AUTOSAR XML (schema 00044)
package /E40_Platform_System_SystemPackage/Components
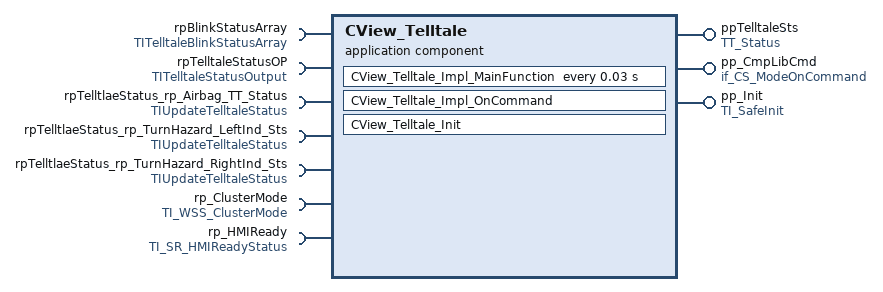
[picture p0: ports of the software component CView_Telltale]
  application sw component type CView_Telltale
    provide port ppTelltaleSts: nonqueued-sender-com-spec{data-element=TT_StatusData, init-value=constant-reference=CView_TelltaleTT_StatusDataValue0}, provided-interface=TT_Status
    provide port pp_CmpLibCmd: server-com-spec{operation=Impl_OnCommand, queue-length=1}, provided-interface=if_CS_ModeOnCommand
    provide port pp_Init: server-com-spec{operation=Init, queue-length=1}, provided-interface=TI_SafeInit
    7 x require port:
      rpBlinkStatusArray: required-interface=TITelltaleBlinkStatusArray
        required-com-specs:
          data-element=TTBlinkStatusArray, init-value=constant-reference=CView_TelltaleTTBlinkStatusArrayValue0
          data-element=TTdummyDataForTypes, init-value=constant-reference=CView_TelltaleTTdummyDataForTypesValue0
      rpTelltaleStatusOP: nonqueued-receiver-com-spec{data-element=TelltaleOpArray, init-value=constant-reference=CView_TelltaleTelltaleOpArrayValue0}, required-interface=TITelltaleStatusOutput
      rpTelltlaeStatus_rp_Airbag_TT_Status: nonqueued-receiver-com-spec{data-element=CurrentTelltaleStatus, init-value=constant-reference=CView_TelltaleCurrentTelltaleStatusValue0}, required-interface=TIUpdateTelltaleStatus
      rpTelltlaeStatus_rp_TurnHazard_LeftInd_Sts: nonqueued-receiver-com-spec{data-element=CurrentTelltaleStatus, init-value=constant-reference=CView_TelltaleCurrentTelltaleStatusValue0}, required-interface=TIUpdateTelltaleStatus
      rpTelltlaeStatus_rp_TurnHazard_RightInd_Sts: nonqueued-receiver-com-spec{data-element=CurrentTelltaleStatus, init-value=constant-reference=CView_TelltaleCurrentTelltaleStatusValue0}, required-interface=TIUpdateTelltaleStatus
      rp_ClusterMode: nonqueued-receiver-com-spec{data-element=WSSCurrentClusterMode, init-value=constant-reference=CView_TelltaleWSSCurrentClusterModeValue0}, required-interface=TI_WSS_ClusterMode
      rp_HMIReady: nonqueued-receiver-com-spec{data-element=HMI_ReadyStatus, init-value=constant-reference=CView_TelltaleHMI_ReadyStatusValue0}, required-interface=TI_SR_HMIReadyStatus
    behavior IB_CView_Telltale
      timing event TECView_Telltale_Impl_MainFunction: start-on-event=CView_Telltale_Impl_MainFunction, period=0.03
      operation invoked event OIE_pp_CmpLibCmd_CView_Telltale_Impl_OnCommandTrigByImpl_OnCommand: start-on-event=CView_Telltale_Impl_OnCommand, operation=pp_CmpLibCmd.Impl_OnCommand
      operation invoked event OIE_pp_Init_CView_Telltale_InitTrigByInit: start-on-event=CView_Telltale_Init, operation=pp_Init.Init
      port-api-options:
        enable-take-address=false, indirect-api=false, port=ppTelltaleSts
        enable-take-address=false, indirect-api=false, port=pp_CmpLibCmd
        enable-take-address=false, indirect-api=false, port=pp_Init
        enable-take-address=false, indirect-api=false, port=rpBlinkStatusArray
        enable-take-address=false, indirect-api=false, port=rpTelltaleStatusOP
        enable-take-address=false, indirect-api=false, port=rpTelltlaeStatus_rp_Airbag_TT_Status
        enable-take-address=false, indirect-api=false, port=rpTelltlaeStatus_rp_TurnHazard_LeftInd_Sts
        enable-take-address=false, indirect-api=false, port=rpTelltlaeStatus_rp_TurnHazard_RightInd_Sts
        enable-take-address=false, indirect-api=false, port=rp_ClusterMode
        enable-take-address=false, indirect-api=false, port=rp_HMIReady
      runnable CView_Telltale_Impl_MainFunction: can-be-invoked-concurrently=true
        data-receive-point-by-arguments:
          8 x access:
            DRA_rpBlinkStatusArray_TTBlinkStatusArray: accessed-variable=rpBlinkStatusArray.TTBlinkStatusArray
            DRA_rpBlinkStatusArray_TTdummyDataForTypes: accessed-variable=rpBlinkStatusArray.TTdummyDataForTypes
            DRA_rpTelltaleStatusOP_TelltaleOpArray: accessed-variable=rpTelltaleStatusOP.TelltaleOpArray
            DRA_rpTelltlaeStatus_rp_Airbag_TT_Status_CurrentTelltaleStatus: accessed-variable=rpTelltlaeStatus_rp_Airbag_TT_Status.CurrentTelltaleStatus
            DRA_rpTelltlaeStatus_rp_TurnHazard_LeftInd_Sts_CurrentTelltaleStatus: accessed-variable=rpTelltlaeStatus_rp_TurnHazard_LeftInd_Sts.CurrentTelltaleStatus
            DRA_rpTelltlaeStatus_rp_TurnHazard_RightInd_Sts_CurrentTelltaleStatus: accessed-variable=rpTelltlaeStatus_rp_TurnHazard_RightInd_Sts.CurrentTelltaleStatus
            DRA_rp_ClusterMode_WSSCurrentClusterMode: accessed-variable=rp_ClusterMode.WSSCurrentClusterMode
            DRA_rp_HMIReady_HMI_ReadyStatus: accessed-variable=rp_HMIReady.HMI_ReadyStatus
        data-send-points:
          access DWA_ppTelltaleSts_TT_StatusData: accessed-variable=ppTelltaleSts.TT_StatusData
      runnable CView_Telltale_Impl_OnCommand: can-be-invoked-concurrently=true
      runnable CView_Telltale_Init: can-be-invoked-concurrently=true
  swc implementation IMPL_CView_Telltale: behavior=IB_CView_Telltale
